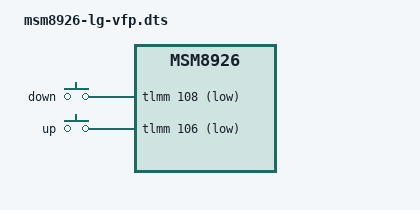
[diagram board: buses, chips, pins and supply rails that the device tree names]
// SPDX-License-Identifier: BSD-3-Clause

#include <skeleton32.dtsi>
#include <lk2nd.dtsi>

/ {
	qcom,msm-id = <QCOM_ID_MSM8926 0>;
	qcom,board-id = <202 0>;
};

&lk2nd {
	model = "LG Wine Smart D486";
	compatible = "lg,vfp";

	lk2nd,dtb-files = "msm8926-lg-vfp";

	gpio-keys {
		compatible = "gpio-keys";
		down {
			lk2nd,code = <KEY_VOLUMEDOWN>;
			gpios = <&tlmm 108 (GPIO_ACTIVE_LOW | GPIO_PULL_UP)>;
		};
		up {
			lk2nd,code = <KEY_VOLUMEUP>;
			gpios = <&tlmm 106 (GPIO_ACTIVE_LOW | GPIO_PULL_UP)>;
		};
	};
};
